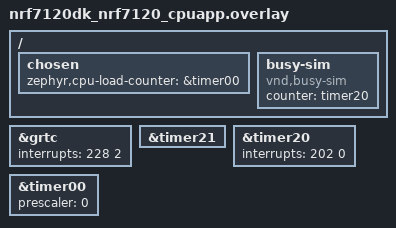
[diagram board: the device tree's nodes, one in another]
/*
 * Copyright (c) 2026 Nordic Semiconductor ASA
 *
 * SPDX-License-Identifier: Apache-2.0
 */

&grtc {
	interrupts = <228 2>;
};

test_timer: &timer21 {
	status = "okay";
	/*interrupts = <203 1>; from .dtsi file*/
};

&timer20 {
	interrupts = <202 0>;
	status = "okay";
};

&timer00 {
	prescaler = <0>;
	status = "okay";
};

/ {
	chosen {
		zephyr,cpu-load-counter = &timer00;
	};

	busy-sim {
		compatible = "vnd,busy-sim";
		counter = <&timer20>;
		status = "okay";
	};
};
